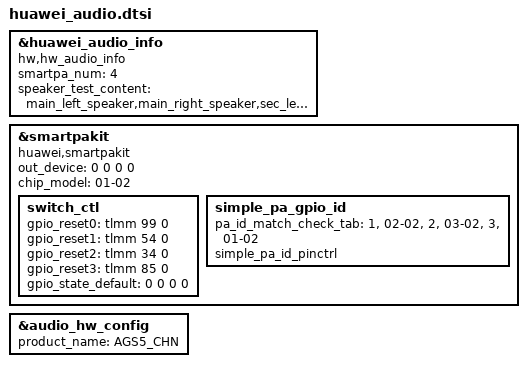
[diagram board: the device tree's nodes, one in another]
&huawei_audio_info {
	compatible = "hw,hw_audio_info";
	smartpa_num = <4>;
	status = "ok";
	speaker_test_content = "main_left_speaker,main_right_speaker,sec_left_speaker,sec_right_speaker";
};

&smartpakit {
	compatible = "huawei,smartpakit";
	/* algo_in params need match out_device for smartpa.
	 * Now, up to only support eight pa, so out_device = <0 0 0 0 0 0 0 0>;
	 * 1. This array is arranged in the following order:
	 *    <0 1 2 3>
	 *    <pril prir secl secr>
	 * 2. This array element value is 0 or 1:
	 *    smartpa: 0 speaker, 1 receiver
	 *    simple pa: out_device not applicable, only set 0 to indicate pa_num
	 * 3. The length of this array is variable, for example:
	 *    single pa: out_device = <0>;
	 *    two pa: out_device = <0 0>;
	 *    four pa: out_device = <1 1 0 0>;
	 *    eight pa: out_device = <0 0 0 0 0 0 0 0>; */
	out_device = <0 0 0 0>;
	/* param_version: 1 mixed smartpa param support */
	status = "ok";
	/* chip_model:
	 * 01-01 : aw-ovs
	 * 01-02 : aw-chn
	 * 02-01 : fs-ovs
	 * 02-02 : fs-chn
	 * 03-01 : sia-ovs
	 * 03-02 : sia-chn
	 */
	chip_model = "01-02";
	switch_ctl {
		gpio_reset0 = <&tlmm 99 0>;
		gpio_reset1 = <&tlmm 54 0>;
		gpio_reset2 = <&tlmm 34 0>;
		gpio_reset3 = <&tlmm 85 0>;
		gpio_state_default = <0 0 0 0>;
	};

	simple_pa_gpio_id {
		pa_id_match_check_tab =
			"1", "02-02",
			"2", "03-02",
			"3", "01-02";
		simple_pa_id_pinctrl;
	};
};

&audio_hw_config {
	product_name = "AGS5_CHN";
};
